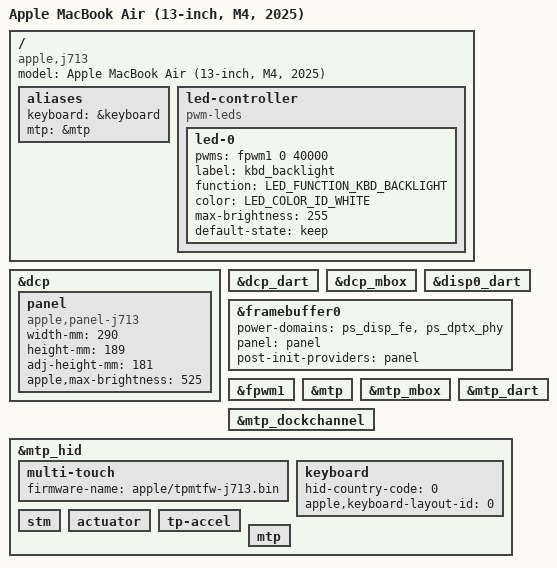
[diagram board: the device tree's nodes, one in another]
// SPDX-License-Identifier: GPL-2.0+ OR MIT
/*
 * Apple MacBook Air (13-inch, M4, 2025)
 *
 * target-type: J713
 *
 * Copyright The Asahi Linux Contributors
 */

/dts-v1/;

#include "t8132.dtsi"
#include "t8132-jxxx.dtsi"
#include "t8132-gpu.dtsi"
#include <dt-bindings/leds/common.h>

/ {
	compatible = "apple,j713", "apple,t8132", "apple,arm-platform";
	model = "Apple MacBook Air (13-inch, M4, 2025)";

	aliases {
		keyboard = &keyboard;
		/* m1n1 maps the iBoot-provided MTP segments through this alias. */
		mtp = &mtp;
		/*
		 * No external display support yet. m1n1 enables every DCP behind a
		 * dcpextN alias that the ADT lists, but not its DARTs or mailbox;
		 * appledrm then never finishes init and boot blocks before userspace.
		 */
		/delete-property/ dcpext0;
		/delete-property/ dcpext1;
	};

	led-controller {
		compatible = "pwm-leds";
		led-0 {
			pwms = <&fpwm1 0 40000>;
			label = "kbd_backlight";
			function = LED_FUNCTION_KBD_BACKLIGHT;
			color = <LED_COLOR_ID_WHITE>;
			max-brightness = <255>;
			default-state = "keep";
		};
	};
};

&dcp {
	status = "okay";

	panel: panel {
		compatible = "apple,panel-j713", "apple,panel";
		/*
		 * Unverified on J713: dimensions and brightness are taken from
		 * the M2 MacBook Air 13" (J413), which uses a 13.6" panel of the
		 * same size.
		 */
		width-mm = <290>;
		height-mm = <189>;
		adj-height-mm = <181>;
		apple,max-brightness = <525>;
	};
};

&dcp_dart {
	status = "okay";
};

&dcp_mbox {
	status = "okay";
};

&disp0_dart {
	status = "okay";
};

/*
 * The firmware-owned display CPU domain is locked on T8132; referencing it
 * holds simpledrm back until the deferred-probe timeout. Use the managed
 * display FE domain, as J773g does.
 */
&framebuffer0 {
	power-domains = <&ps_disp_fe>, <&ps_dptx_phy>;
	panel = <&panel>;
	post-init-providers = <&panel>;
};

&fpwm1 {
	status = "okay";
};

&mtp {
	status = "okay";
};

&mtp_mbox {
	status = "okay";
};

&mtp_dart {
	status = "okay";
};

&mtp_dockchannel {
	status = "okay";
};

&mtp_hid {
	status = "okay";

	multi-touch {
		firmware-name = "apple/tpmtfw-j713.bin";
	};

	keyboard: keyboard {
		hid-country-code = <0>;
		apple,keyboard-layout-id = <0>;
	};

	stm {
	};

	actuator {
	};

	tp-accel {
	};

	mtp {
	};
};
